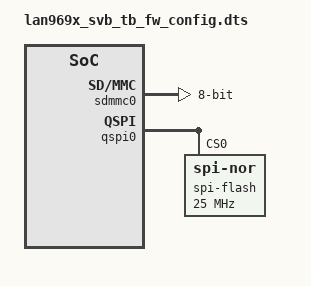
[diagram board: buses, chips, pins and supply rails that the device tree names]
/*
 * Copyright (c) 2022, Microchip Technology Inc. and its subsidiaries.
 *
 * SPDX-License-Identifier: BSD-3-Clause
 */

/dts-v1/;

#include "lan969x.dtsi"
#include "lan969x-ddr3.dtsi"

&emmc_clk {
	clock-frequency = <52000000>;
};

&sdmmc0 {
	status = "okay";
	bus-width = <8>;
};

&qspi0 {
	status = "okay";
	spi-flash@0 {
		compatible = "jedec,spi-nor";
		reg = <0>;
		spi-max-frequency = <25000000>;
		spi-tx-bus-width = <4>;
		spi-rx-bus-width = <4>;
	};
};

&board {
	board-number = <200>; /* Unable to probe SVB correctly */
};
